# S32K324_M7 register map
Vendor: NXP Semiconductors; File version: 1.1
CPU: CM7 r0p1, little endian, MPU, FPU, VTOR, 4 interrupt priority bits
Registers are 32-bit, read-write, reset 0x0 unless marked. A register's access mark holds for its fields unless they carry their own. Offsets are from the block's base; [hi:lo] are bit positions; {n}, {i} and the like mark numbered series; 'fields as' and 'values as' point back to an identical list.

## SIUL2
Base 0x40290000
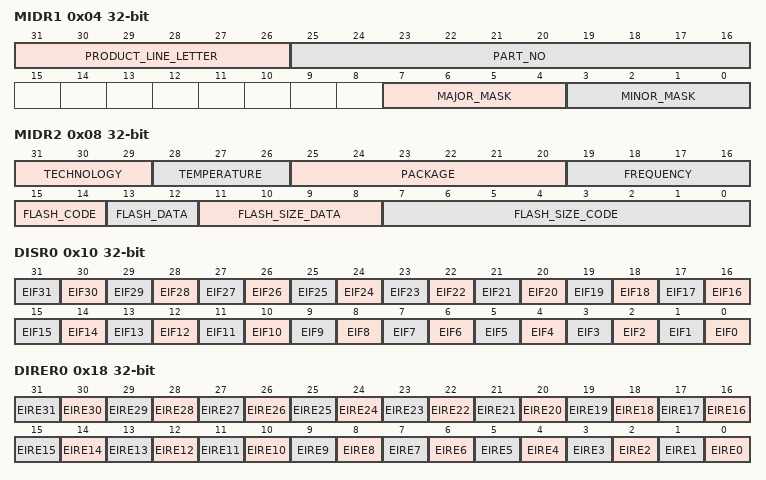
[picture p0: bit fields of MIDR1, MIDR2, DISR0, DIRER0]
0x04 MIDR1 ro reset not defined — SIUL2 MCU ID Register 1
  [31:26] PRODUCT_LINE_LETTER
  [25:16] PART_NO — MCU Part Number
  [7:4] MAJOR_MASK — Major Mask Revision
  [3:0] MINOR_MASK — Minor Mask Revision
0x08 MIDR2 ro reset not defined — SIUL2 MCU ID Register 2
  [31:29] TECHNOLOGY
    1=C40EFS3
  [28:26] TEMPERATURE
    4=M = 125C
  [25:20] PACKAGE
    3=257-MAPBGA; 35=100-MAXQFP; 38=172-MAXQFP
  [19:16] FREQUENCY
    3=120 MHz; 4=160 MHz; 5=240 MHz
  [15:14] FLASH_CODE
    2=Monolithic
  [13:12] FLASH_DATA
    2=Monolithic
  [11:8] FLASH_SIZE_DATA
    0=64KB; 1=128KB; 2=256KB
  [7:0] FLASH_SIZE_CODE
    2=512kB; 4=1MB; 8=2.00MB; 12=3.00MB; 16=4.00MB; 24=6.00MB; 32=8.00MB
0x10 DISR0 write-1-clears — SIUL2 DMA/Interrupt Status Flag Register0
  [n] EIF{n} write-1-clears (n=0..31) — External Interrupt Status Flag {n}
    0=EIF_NO (No interrupt event has occurred on the pad.); 1=EIF_YES (An interrupt event as defined by IREER{n} and IFEER{n} has occurred.)
0x18 DIRER0 — SIUL2 DMA/Interrupt Request Enable Register0
  [all] fields
    0=EIRE_DISABLED (Disabled); 1=EIRE_ENABLED (Enabled)
  [n] EIRE{n} (n=0..31) — External Interrupt Request Enable
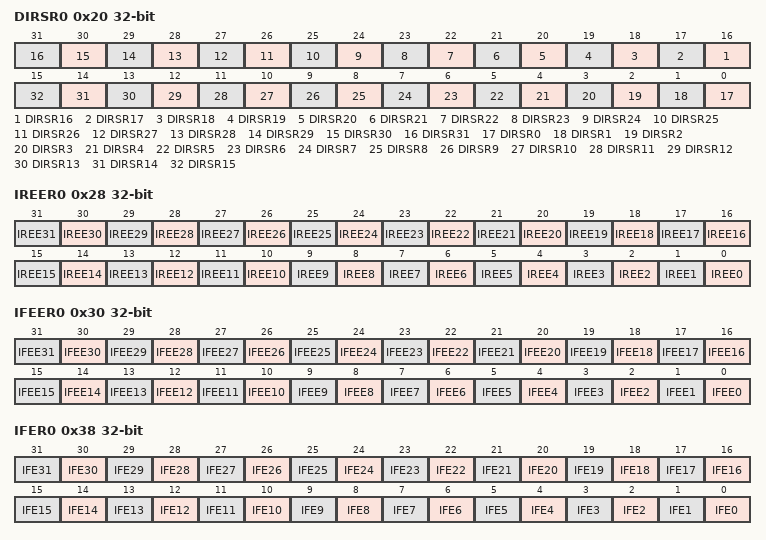
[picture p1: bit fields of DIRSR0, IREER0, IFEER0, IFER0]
0x20 DIRSR0 — SIUL2 DMA/Interrupt Request Select Register0
  [n] DIRSR{n} (n=16..31) — DMA/Interrupt Request Select Register
    0=DISR_INT (Interrupt request)
  [n] DIRSR{n} (n=0..15) — DMA/Interrupt Request Select Register
    0=DISR_INT (Interrupt request); 1=DISR_DMA (DMA request)
0x28 IREER0 — SIUL2 Interrupt Rising-Edge Event Enable Register 0
  [all] fields
    0=IREE_DISABLED (Disabled); 1=IREE_ENABLED (Enabled)
  [n] IREE{n} (n=0..31) — Enables rising-edge events to set DISR0[EIF{n}].
0x30 IFEER0 — SIUL2 Interrupt Falling-Edge Event Enable Register 0
  [all] fields
    0=IFEE_DISABLED (Disabled); 1=IFEE_ENABLED (Enabled)
  [n] IFEE{n} (n=0..31) — Enables falling-edge events to set DISR0[EIF{n}].
0x38 IFER0 — SIUL2 Interrupt Filter Enable Register 0
  [all] fields
    0=IFE_DISABLED (Disabled); 1=IFE_ENABLED (Enabled)
  [n] IFE{n} (n=0..31) — Enables digital glitch filter on the interrupt pad input.
{0x40+4i} IFMCR{i} (i=0..31) — SIUL2 Interrupt Filter Maximum Counter Register
  [3:0] MAXCNT — Maximum Interrupt Filter Counter setting
0xC0 IFCPR — SIUL2 Interrupt Filter Clock Prescaler Register
  [3:0] IFCP — Interrupt Filter Clock Prescaler setting
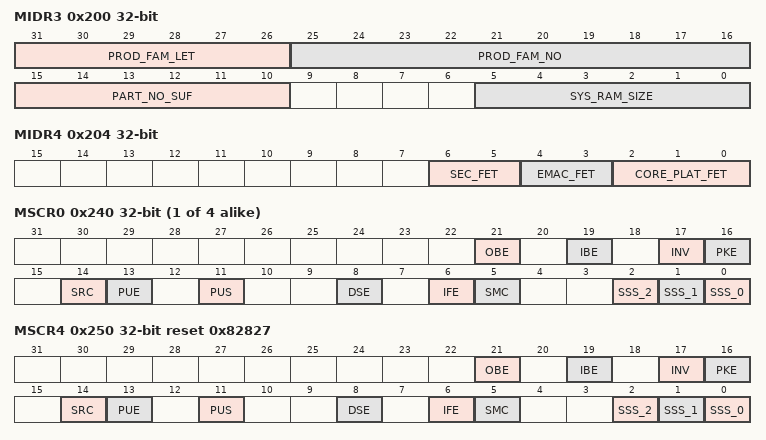
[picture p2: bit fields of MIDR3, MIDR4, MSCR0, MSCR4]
0x200 MIDR3 ro reset not defined — SIUL2 MCU ID Register 3
  [31:26] PROD_FAM_LET — Product Family Letter
    19=S
  [25:16] PROD_FAM_NO — Product Family Number
    32=32
  [15:10] PART_NO_SUF — Part Number Suffix
    0=None
  [5:0] SYS_RAM_SIZE — System RAM Size
    2=128kB; 3=192kB; 4=256kB; 6=512kB
0x204 MIDR4 ro reset not defined — SIUL2 MCU ID Register 4
  [6:5] SEC_FET — Security Feature
    1=HSE-B
  [4:3] EMAC_FET — Ethernet Feature
    0=No Ethernet; 1=Ethernet present
  [2:0] CORE_PLAT_FET — Core Platform Options Feature
    0=Single core; 1=Dual core; 2=1x lock-step core; 3=1x lock-step core + 1 perf. core; 4=Triple core
{0x240+4i} MSCR{i} (i=0..3) — SIUL2 Multiplexed Signal Configuration Register
  [21] OBE — GPIO Output Buffer Enable
    0=Output driver disabled; 1=Output driver enabled
  [19] IBE — Input Buffer Enable
    0=Disabled; 1=Enabled
  [17] INV — Invert
    0=Don't invert; 1=Invert
  [16] PKE — Pad keeping enable
    0=Disabled; 1=Enabled
  [14] SRC — Slew Rate Control
    0=Fastest setting; 1=Slowest setting
  [13] PUE — Pull Enable
    0=Disabled; 1=Enabled
  [11] PUS — Pull Select
    0=Pull down; 1=Pull up
  [8] DSE
    0=Disabled; 1=Enabled
  [6] IFE
    0=Disabled; 1=Enabled
  [5] SMC — Safe Mode Control
    0=Disable (The output buffer returns to its previous state when the chip leaves Safe mode.); 1=Don't disable
  [2] SSS_2 — Source Signal Select_2
  [1] SSS_1 — Source Signal Select_1
  [0] SSS_0 — Source Signal Select_0
0x250 MSCR4 reset 0x82827 — SIUL2 Multiplexed Signal Configuration Register
  fields as MSCR0
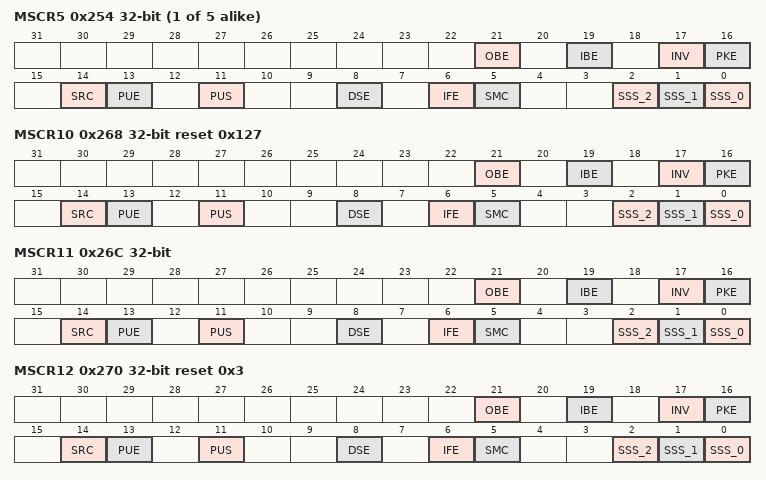
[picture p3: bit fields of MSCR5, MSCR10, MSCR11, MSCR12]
{0x240+4i} MSCR{i} (i=5..9) — SIUL2 Multiplexed Signal Configuration Register
  fields as MSCR0
0x268 MSCR10 reset 0x127 — SIUL2 Multiplexed Signal Configuration Register
  fields as MSCR0
0x26C MSCR11 — SIUL2 Multiplexed Signal Configuration Register
  fields as MSCR0
0x270 MSCR12 reset 0x3 — SIUL2 Multiplexed Signal Configuration Register
  fields as MSCR0
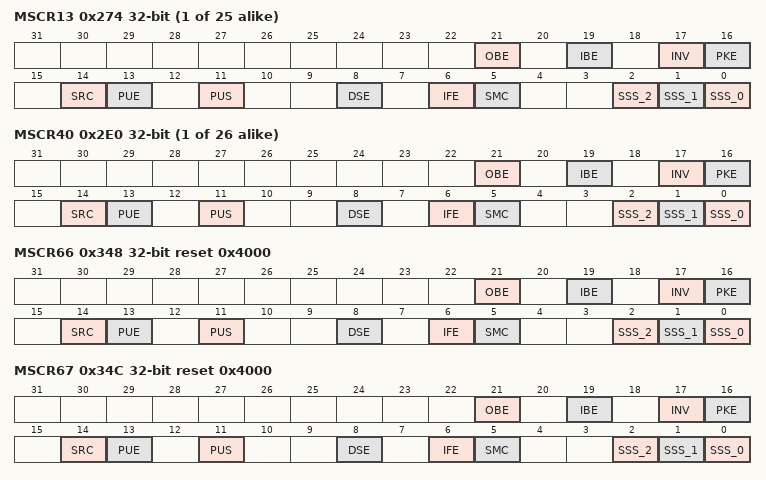
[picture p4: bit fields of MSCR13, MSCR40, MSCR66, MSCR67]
{0x240+4i} MSCR{i} (i=13..37) — SIUL2 Multiplexed Signal Configuration Register
  fields as MSCR0
{0x240+4i} MSCR{i} (i=40..65) — SIUL2 Multiplexed Signal Configuration Register
  fields as MSCR0
0x348 MSCR66 reset 0x4000 — SIUL2 Multiplexed Signal Configuration Register
  fields as MSCR0
0x34C MSCR67 reset 0x4000 — SIUL2 Multiplexed Signal Configuration Register
  fields as MSCR0
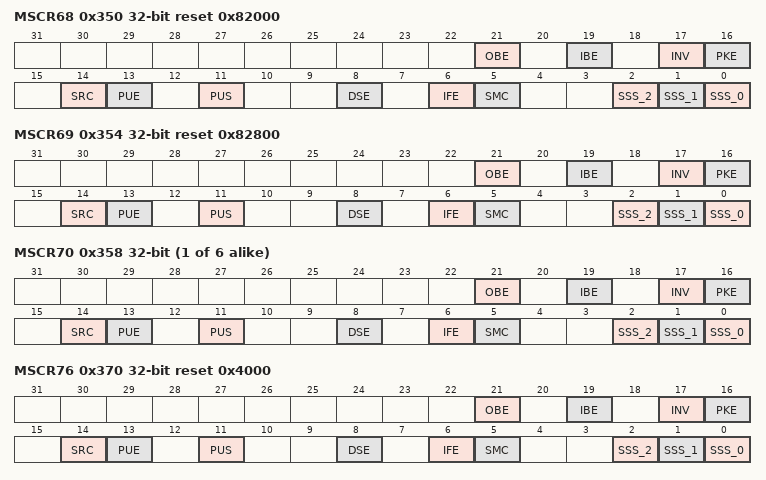
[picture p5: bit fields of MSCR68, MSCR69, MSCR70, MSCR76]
0x350 MSCR68 reset 0x82000 — SIUL2 Multiplexed Signal Configuration Register
  fields as MSCR0
0x354 MSCR69 reset 0x82800 — SIUL2 Multiplexed Signal Configuration Register
  fields as MSCR0
{0x240+4i} MSCR{i} (i=70..75) — SIUL2 Multiplexed Signal Configuration Register
  fields as MSCR0
0x370 MSCR76 reset 0x4000 — SIUL2 Multiplexed Signal Configuration Register
  fields as MSCR0
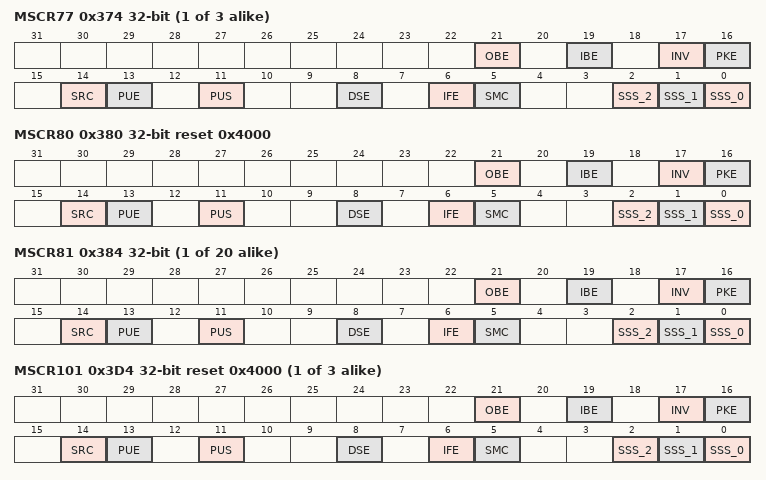
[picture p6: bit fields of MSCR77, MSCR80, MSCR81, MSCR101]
{0x240+4i} MSCR{i} (i=77..79) — SIUL2 Multiplexed Signal Configuration Register
  fields as MSCR0
0x380 MSCR80 reset 0x4000 — SIUL2 Multiplexed Signal Configuration Register
  fields as MSCR0
{0x240+4i} MSCR{i} (i=81..100) — SIUL2 Multiplexed Signal Configuration Register
  fields as MSCR0
{0x240+4i} MSCR{i} reset 0x4000 (i=101..103) — SIUL2 Multiplexed Signal Configuration Register
  fields as MSCR0
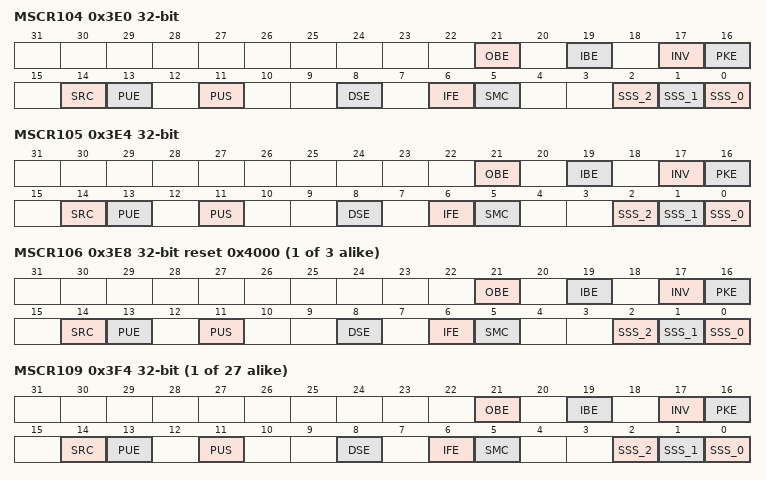
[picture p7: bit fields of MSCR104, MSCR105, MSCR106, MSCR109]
0x3E0 MSCR104 — SIUL2 Multiplexed Signal Configuration Register
  fields as MSCR0
0x3E4 MSCR105 — SIUL2 Multiplexed Signal Configuration Register
  fields as MSCR0
{0x240+4i} MSCR{i} reset 0x4000 (i=106..108) — SIUL2 Multiplexed Signal Configuration Register
  fields as MSCR0
{0x240+4i} MSCR{i} (i=109..135) — SIUL2 Multiplexed Signal Configuration Register
  fields as MSCR0
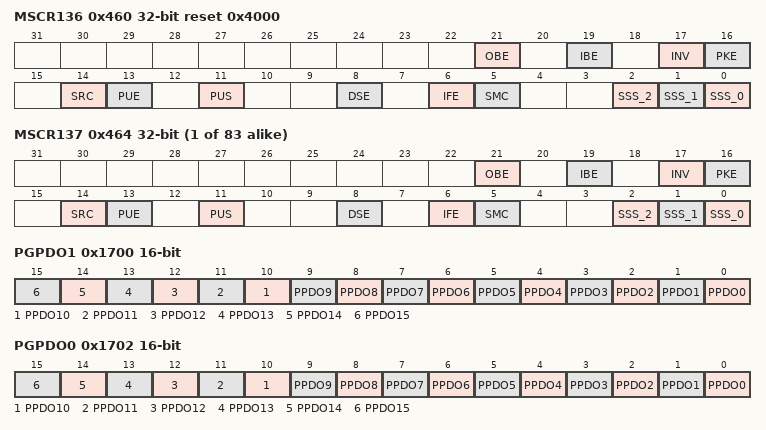
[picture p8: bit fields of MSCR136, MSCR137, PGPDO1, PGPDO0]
0x460 MSCR136 reset 0x4000 — SIUL2 Multiplexed Signal Configuration Register
  fields as MSCR0
{0x240+4i} MSCR{i} (i=137..219) — SIUL2 Multiplexed Signal Configuration Register
  fields as MSCR0
{0xA40+4i} IMCR{i} (i=0..5) — SIUL2 Input Multiplexed Signal Configuration Register
  [3:0] SSS — Source Signal Select
{0xA40+4i} IMCR{i} (i=16..71) — SIUL2 Input Multiplexed Signal Configuration Register
  [3:0] SSS — Source Signal Select
{0xA40+4i} IMCR{i} (i=80..103) — SIUL2 Input Multiplexed Signal Configuration Register
  [3:0] SSS — Source Signal Select
{0xA40+4i} IMCR{i} (i=112..135) — SIUL2 Input Multiplexed Signal Configuration Register
  [3:0] SSS — Source Signal Select
{0xA40+4i} IMCR{i} (i=144..149) — SIUL2 Input Multiplexed Signal Configuration Register
  [3:0] SSS — Source Signal Select
{0xA40+4i} IMCR{i} (i=152..202) — SIUL2 Input Multiplexed Signal Configuration Register
  [3:0] SSS — Source Signal Select
{0xA40+4i} IMCR{i} (i=211..268) — SIUL2 Input Multiplexed Signal Configuration Register
  [3:0] SSS — Source Signal Select
{0xA40+4i} IMCR{i} (i=289..309) — SIUL2 Input Multiplexed Signal Configuration Register
  [3:0] SSS — Source Signal Select
{0xA40+4i} IMCR{i} (i=315..325) — SIUL2 Input Multiplexed Signal Configuration Register
  [3:0] SSS — Source Signal Select
{0xA40+4i} IMCR{i} (i=343..378) — SIUL2 Input Multiplexed Signal Configuration Register
  [3:0] SSS — Source Signal Select
0x1300 GPDO3 8-bit — SIUL2 GPIO Pad Data Output Register
  [0] PDO_n — Pad Data Out
    0=PDO_a_LOW (Pad Data Out Low); 1=PDO_a_HIGH (Pad Data Out High)
0x1301 GPDO2 8-bit — SIUL2 GPIO Pad Data Output Register
  fields as GPDO3
0x1302 GPDO1 8-bit — SIUL2 GPIO Pad Data Output Register
  fields as GPDO3
0x1303 GPDO0 8-bit — SIUL2 GPIO Pad Data Output Register
  fields as GPDO3
0x1304 GPDO7 8-bit — SIUL2 GPIO Pad Data Output Register
  fields as GPDO3
0x1305 GPDO6 8-bit — SIUL2 GPIO Pad Data Output Register
  fields as GPDO3
0x1306 GPDO5 8-bit — SIUL2 GPIO Pad Data Output Register
  fields as GPDO3
0x1307 GPDO4 8-bit — SIUL2 GPIO Pad Data Output Register
  fields as GPDO3
0x1308 GPDO11 8-bit — SIUL2 GPIO Pad Data Output Register
  fields as GPDO3
0x1309 GPDO10 8-bit — SIUL2 GPIO Pad Data Output Register
  fields as GPDO3
0x130A GPDO9 8-bit — SIUL2 GPIO Pad Data Output Register
  fields as GPDO3
0x130B GPDO8 8-bit — SIUL2 GPIO Pad Data Output Register
  fields as GPDO3
0x130C GPDO15 8-bit — SIUL2 GPIO Pad Data Output Register
  fields as GPDO3
0x130D GPDO14 8-bit — SIUL2 GPIO Pad Data Output Register
  fields as GPDO3
0x130E GPDO13 8-bit — SIUL2 GPIO Pad Data Output Register
  fields as GPDO3
0x130F GPDO12 8-bit — SIUL2 GPIO Pad Data Output Register
  fields as GPDO3
0x1310 GPDO19 8-bit — SIUL2 GPIO Pad Data Output Register
  fields as GPDO3
0x1311 GPDO18 8-bit — SIUL2 GPIO Pad Data Output Register
  fields as GPDO3
0x1312 GPDO17 8-bit — SIUL2 GPIO Pad Data Output Register
  fields as GPDO3
0x1313 GPDO16 8-bit — SIUL2 GPIO Pad Data Output Register
  fields as GPDO3
0x1314 GPDO23 8-bit — SIUL2 GPIO Pad Data Output Register
  fields as GPDO3
0x1315 GPDO22 8-bit — SIUL2 GPIO Pad Data Output Register
  fields as GPDO3
0x1316 GPDO21 8-bit — SIUL2 GPIO Pad Data Output Register
  fields as GPDO3
0x1317 GPDO20 8-bit — SIUL2 GPIO Pad Data Output Register
  fields as GPDO3
0x1318 GPDO27 8-bit — SIUL2 GPIO Pad Data Output Register
  fields as GPDO3
0x1319 GPDO26 8-bit — SIUL2 GPIO Pad Data Output Register
  fields as GPDO3
0x131A GPDO25 8-bit — SIUL2 GPIO Pad Data Output Register
  fields as GPDO3
0x131B GPDO24 8-bit — SIUL2 GPIO Pad Data Output Register
  fields as GPDO3
0x131C GPDO31 8-bit — SIUL2 GPIO Pad Data Output Register
  fields as GPDO3
0x131D GPDO30 8-bit — SIUL2 GPIO Pad Data Output Register
  fields as GPDO3
0x131E GPDO29 8-bit — SIUL2 GPIO Pad Data Output Register
  fields as GPDO3
0x131F GPDO28 8-bit — SIUL2 GPIO Pad Data Output Register
  fields as GPDO3
0x1320 GPDO35 8-bit — SIUL2 GPIO Pad Data Output Register
  fields as GPDO3
0x1321 GPDO34 8-bit — SIUL2 GPIO Pad Data Output Register
  fields as GPDO3
0x1322 GPDO33 8-bit — SIUL2 GPIO Pad Data Output Register
  fields as GPDO3
0x1323 GPDO32 8-bit — SIUL2 GPIO Pad Data Output Register
  fields as GPDO3
0x1326 GPDO37 8-bit — SIUL2 GPIO Pad Data Output Register
  fields as GPDO3
0x1327 GPDO36 8-bit — SIUL2 GPIO Pad Data Output Register
  fields as GPDO3
0x1328 GPDO43 8-bit — SIUL2 GPIO Pad Data Output Register
  fields as GPDO3
0x1329 GPDO42 8-bit — SIUL2 GPIO Pad Data Output Register
  fields as GPDO3
0x132A GPDO41 8-bit — SIUL2 GPIO Pad Data Output Register
  fields as GPDO3
0x132B GPDO40 8-bit — SIUL2 GPIO Pad Data Output Register
  fields as GPDO3
0x132C GPDO47 8-bit — SIUL2 GPIO Pad Data Output Register
  fields as GPDO3
0x132D GPDO46 8-bit — SIUL2 GPIO Pad Data Output Register
  fields as GPDO3
0x132E GPDO45 8-bit — SIUL2 GPIO Pad Data Output Register
  fields as GPDO3
0x132F GPDO44 8-bit — SIUL2 GPIO Pad Data Output Register
  fields as GPDO3
0x1330 GPDO51 8-bit — SIUL2 GPIO Pad Data Output Register
  fields as GPDO3
0x1331 GPDO50 8-bit — SIUL2 GPIO Pad Data Output Register
  fields as GPDO3
0x1332 GPDO49 8-bit — SIUL2 GPIO Pad Data Output Register
  fields as GPDO3
0x1333 GPDO48 8-bit — SIUL2 GPIO Pad Data Output Register
  fields as GPDO3
0x1334 GPDO55 8-bit — SIUL2 GPIO Pad Data Output Register
  fields as GPDO3
0x1335 GPDO54 8-bit — SIUL2 GPIO Pad Data Output Register
  fields as GPDO3
0x1336 GPDO53 8-bit — SIUL2 GPIO Pad Data Output Register
  fields as GPDO3
0x1337 GPDO52 8-bit — SIUL2 GPIO Pad Data Output Register
  fields as GPDO3
0x1338 GPDO59 8-bit — SIUL2 GPIO Pad Data Output Register
  fields as GPDO3
0x1339 GPDO58 8-bit — SIUL2 GPIO Pad Data Output Register
  fields as GPDO3
0x133A GPDO57 8-bit — SIUL2 GPIO Pad Data Output Register
  fields as GPDO3
0x133B GPDO56 8-bit — SIUL2 GPIO Pad Data Output Register
  fields as GPDO3
0x133C GPDO63 8-bit — SIUL2 GPIO Pad Data Output Register
  fields as GPDO3
0x133D GPDO62 8-bit — SIUL2 GPIO Pad Data Output Register
  fields as GPDO3
0x133E GPDO61 8-bit — SIUL2 GPIO Pad Data Output Register
  fields as GPDO3
0x133F GPDO60 8-bit — SIUL2 GPIO Pad Data Output Register
  fields as GPDO3
0x1340 GPDO67 8-bit — SIUL2 GPIO Pad Data Output Register
  fields as GPDO3
0x1341 GPDO66 8-bit — SIUL2 GPIO Pad Data Output Register
  fields as GPDO3
0x1342 GPDO65 8-bit — SIUL2 GPIO Pad Data Output Register
  fields as GPDO3
0x1343 GPDO64 8-bit — SIUL2 GPIO Pad Data Output Register
  fields as GPDO3
0x1344 GPDO71 8-bit — SIUL2 GPIO Pad Data Output Register
  fields as GPDO3
0x1345 GPDO70 8-bit — SIUL2 GPIO Pad Data Output Register
  fields as GPDO3
0x1346 GPDO69 8-bit — SIUL2 GPIO Pad Data Output Register
  fields as GPDO3
0x1347 GPDO68 8-bit — SIUL2 GPIO Pad Data Output Register
  fields as GPDO3
0x1348 GPDO75 8-bit — SIUL2 GPIO Pad Data Output Register
  fields as GPDO3
0x1349 GPDO74 8-bit — SIUL2 GPIO Pad Data Output Register
  fields as GPDO3
0x134A GPDO73 8-bit — SIUL2 GPIO Pad Data Output Register
  fields as GPDO3
0x134B GPDO72 8-bit — SIUL2 GPIO Pad Data Output Register
  fields as GPDO3
0x134C GPDO79 8-bit — SIUL2 GPIO Pad Data Output Register
  fields as GPDO3
0x134D GPDO78 8-bit — SIUL2 GPIO Pad Data Output Register
  fields as GPDO3
0x134E GPDO77 8-bit — SIUL2 GPIO Pad Data Output Register
  fields as GPDO3
0x134F GPDO76 8-bit — SIUL2 GPIO Pad Data Output Register
  fields as GPDO3
0x1350 GPDO83 8-bit — SIUL2 GPIO Pad Data Output Register
  fields as GPDO3
0x1351 GPDO82 8-bit — SIUL2 GPIO Pad Data Output Register
  fields as GPDO3
0x1352 GPDO81 8-bit — SIUL2 GPIO Pad Data Output Register
  fields as GPDO3
0x1353 GPDO80 8-bit — SIUL2 GPIO Pad Data Output Register
  fields as GPDO3
0x1354 GPDO87 8-bit — SIUL2 GPIO Pad Data Output Register
  fields as GPDO3
0x1355 GPDO86 8-bit — SIUL2 GPIO Pad Data Output Register
  fields as GPDO3
0x1356 GPDO85 8-bit — SIUL2 GPIO Pad Data Output Register
  fields as GPDO3
0x1357 GPDO84 8-bit — SIUL2 GPIO Pad Data Output Register
  fields as GPDO3
0x1358 GPDO91 8-bit — SIUL2 GPIO Pad Data Output Register
  fields as GPDO3
0x1359 GPDO90 8-bit — SIUL2 GPIO Pad Data Output Register
  fields as GPDO3
0x135A GPDO89 8-bit — SIUL2 GPIO Pad Data Output Register
  fields as GPDO3
0x135B GPDO88 8-bit — SIUL2 GPIO Pad Data Output Register
  fields as GPDO3
0x135C GPDO95 8-bit — SIUL2 GPIO Pad Data Output Register
  fields as GPDO3
0x135D GPDO94 8-bit — SIUL2 GPIO Pad Data Output Register
  fields as GPDO3
0x135E GPDO93 8-bit — SIUL2 GPIO Pad Data Output Register
  fields as GPDO3
0x135F GPDO92 8-bit — SIUL2 GPIO Pad Data Output Register
  fields as GPDO3
0x1360 GPDO99 8-bit — SIUL2 GPIO Pad Data Output Register
  fields as GPDO3
0x1361 GPDO98 8-bit — SIUL2 GPIO Pad Data Output Register
  fields as GPDO3
0x1362 GPDO97 8-bit — SIUL2 GPIO Pad Data Output Register
  fields as GPDO3
0x1363 GPDO96 8-bit — SIUL2 GPIO Pad Data Output Register
  fields as GPDO3
0x1364 GPDO103 8-bit — SIUL2 GPIO Pad Data Output Register
  fields as GPDO3
0x1365 GPDO102 8-bit — SIUL2 GPIO Pad Data Output Register
  fields as GPDO3
0x1366 GPDO101 8-bit — SIUL2 GPIO Pad Data Output Register
  fields as GPDO3
0x1367 GPDO100 8-bit — SIUL2 GPIO Pad Data Output Register
  fields as GPDO3
0x1368 GPDO107 8-bit — SIUL2 GPIO Pad Data Output Register
  fields as GPDO3
0x1369 GPDO106 8-bit — SIUL2 GPIO Pad Data Output Register
  fields as GPDO3
0x136A GPDO105 8-bit — SIUL2 GPIO Pad Data Output Register
  fields as GPDO3
0x136B GPDO104 8-bit — SIUL2 GPIO Pad Data Output Register
  fields as GPDO3
0x136C GPDO111 8-bit — SIUL2 GPIO Pad Data Output Register
  fields as GPDO3
0x136D GPDO110 8-bit — SIUL2 GPIO Pad Data Output Register
  fields as GPDO3
0x136E GPDO109 8-bit — SIUL2 GPIO Pad Data Output Register
  fields as GPDO3
0x136F GPDO108 8-bit — SIUL2 GPIO Pad Data Output Register
  fields as GPDO3
0x1370 GPDO115 8-bit — SIUL2 GPIO Pad Data Output Register
  fields as GPDO3
0x1371 GPDO114 8-bit — SIUL2 GPIO Pad Data Output Register
  fields as GPDO3
0x1372 GPDO113 8-bit — SIUL2 GPIO Pad Data Output Register
  fields as GPDO3
0x1373 GPDO112 8-bit — SIUL2 GPIO Pad Data Output Register
  fields as GPDO3
0x1374 GPDO119 8-bit — SIUL2 GPIO Pad Data Output Register
  fields as GPDO3
0x1375 GPDO118 8-bit — SIUL2 GPIO Pad Data Output Register
  fields as GPDO3
0x1376 GPDO117 8-bit — SIUL2 GPIO Pad Data Output Register
  fields as GPDO3
0x1377 GPDO116 8-bit — SIUL2 GPIO Pad Data Output Register
  fields as GPDO3
0x1378 GPDO123 8-bit — SIUL2 GPIO Pad Data Output Register
  fields as GPDO3
0x1379 GPDO122 8-bit — SIUL2 GPIO Pad Data Output Register
  fields as GPDO3
0x137A GPDO121 8-bit — SIUL2 GPIO Pad Data Output Register
  fields as GPDO3
0x137B GPDO120 8-bit — SIUL2 GPIO Pad Data Output Register
  fields as GPDO3
0x137C GPDO127 8-bit — SIUL2 GPIO Pad Data Output Register
  fields as GPDO3
0x137D GPDO126 8-bit — SIUL2 GPIO Pad Data Output Register
  fields as GPDO3
0x137E GPDO125 8-bit — SIUL2 GPIO Pad Data Output Register
  fields as GPDO3
0x137F GPDO124 8-bit — SIUL2 GPIO Pad Data Output Register
  fields as GPDO3
0x1380 GPDO131 8-bit — SIUL2 GPIO Pad Data Output Register
  fields as GPDO3
0x1381 GPDO130 8-bit — SIUL2 GPIO Pad Data Output Register
  fields as GPDO3
0x1382 GPDO129 8-bit — SIUL2 GPIO Pad Data Output Register
  fields as GPDO3
0x1383 GPDO128 8-bit — SIUL2 GPIO Pad Data Output Register
  fields as GPDO3
0x1384 GPDO135 8-bit — SIUL2 GPIO Pad Data Output Register
  fields as GPDO3
0x1385 GPDO134 8-bit — SIUL2 GPIO Pad Data Output Register
  fields as GPDO3
0x1386 GPDO133 8-bit — SIUL2 GPIO Pad Data Output Register
  fields as GPDO3
0x1387 GPDO132 8-bit — SIUL2 GPIO Pad Data Output Register
  fields as GPDO3
0x1388 GPDO139 8-bit — SIUL2 GPIO Pad Data Output Register
  fields as GPDO3
0x1389 GPDO138 8-bit — SIUL2 GPIO Pad Data Output Register
  fields as GPDO3
0x138A GPDO137 8-bit — SIUL2 GPIO Pad Data Output Register
  fields as GPDO3
0x138B GPDO136 8-bit — SIUL2 GPIO Pad Data Output Register
  fields as GPDO3
0x138C GPDO143 8-bit — SIUL2 GPIO Pad Data Output Register
  fields as GPDO3
0x138D GPDO142 8-bit — SIUL2 GPIO Pad Data Output Register
  fields as GPDO3
0x138E GPDO141 8-bit — SIUL2 GPIO Pad Data Output Register
  fields as GPDO3
0x138F GPDO140 8-bit — SIUL2 GPIO Pad Data Output Register
  fields as GPDO3
0x1390 GPDO147 8-bit — SIUL2 GPIO Pad Data Output Register
  fields as GPDO3
0x1391 GPDO146 8-bit — SIUL2 GPIO Pad Data Output Register
  fields as GPDO3
0x1392 GPDO145 8-bit — SIUL2 GPIO Pad Data Output Register
  fields as GPDO3
0x1393 GPDO144 8-bit — SIUL2 GPIO Pad Data Output Register
  fields as GPDO3
0x1394 GPDO151 8-bit — SIUL2 GPIO Pad Data Output Register
  fields as GPDO3
0x1395 GPDO150 8-bit — SIUL2 GPIO Pad Data Output Register
  fields as GPDO3
0x1396 GPDO149 8-bit — SIUL2 GPIO Pad Data Output Register
  fields as GPDO3
0x1397 GPDO148 8-bit — SIUL2 GPIO Pad Data Output Register
  fields as GPDO3
0x1398 GPDO155 8-bit — SIUL2 GPIO Pad Data Output Register
  fields as GPDO3
0x1399 GPDO154 8-bit — SIUL2 GPIO Pad Data Output Register
  fields as GPDO3
0x139A GPDO153 8-bit — SIUL2 GPIO Pad Data Output Register
  fields as GPDO3
0x139B GPDO152 8-bit — SIUL2 GPIO Pad Data Output Register
  fields as GPDO3
0x139C GPDO159 8-bit — SIUL2 GPIO Pad Data Output Register
  fields as GPDO3
0x139D GPDO158 8-bit — SIUL2 GPIO Pad Data Output Register
  fields as GPDO3
0x139E GPDO157 8-bit — SIUL2 GPIO Pad Data Output Register
  fields as GPDO3
0x139F GPDO156 8-bit — SIUL2 GPIO Pad Data Output Register
  fields as GPDO3
0x13A0 GPDO163 8-bit — SIUL2 GPIO Pad Data Output Register
  fields as GPDO3
0x13A1 GPDO162 8-bit — SIUL2 GPIO Pad Data Output Register
  fields as GPDO3
0x13A2 GPDO161 8-bit — SIUL2 GPIO Pad Data Output Register
  fields as GPDO3
0x13A3 GPDO160 8-bit — SIUL2 GPIO Pad Data Output Register
  fields as GPDO3
0x13A4 GPDO167 8-bit — SIUL2 GPIO Pad Data Output Register
  fields as GPDO3
0x13A5 GPDO166 8-bit — SIUL2 GPIO Pad Data Output Register
  fields as GPDO3
0x13A6 GPDO165 8-bit — SIUL2 GPIO Pad Data Output Register
  fields as GPDO3
0x13A7 GPDO164 8-bit — SIUL2 GPIO Pad Data Output Register
  fields as GPDO3
0x13A8 GPDO171 8-bit — SIUL2 GPIO Pad Data Output Register
  fields as GPDO3
0x13A9 GPDO170 8-bit — SIUL2 GPIO Pad Data Output Register
  fields as GPDO3
0x13AA GPDO169 8-bit — SIUL2 GPIO Pad Data Output Register
  fields as GPDO3
0x13AB GPDO168 8-bit — SIUL2 GPIO Pad Data Output Register
  fields as GPDO3
0x13AC GPDO175 8-bit — SIUL2 GPIO Pad Data Output Register
  fields as GPDO3
0x13AD GPDO174 8-bit — SIUL2 GPIO Pad Data Output Register
  fields as GPDO3
0x13AE GPDO173 8-bit — SIUL2 GPIO Pad Data Output Register
  fields as GPDO3
0x13AF GPDO172 8-bit — SIUL2 GPIO Pad Data Output Register
  fields as GPDO3
0x13B0 GPDO179 8-bit — SIUL2 GPIO Pad Data Output Register
  fields as GPDO3
0x13B1 GPDO178 8-bit — SIUL2 GPIO Pad Data Output Register
  fields as GPDO3
0x13B2 GPDO177 8-bit — SIUL2 GPIO Pad Data Output Register
  fields as GPDO3
0x13B3 GPDO176 8-bit — SIUL2 GPIO Pad Data Output Register
  fields as GPDO3
0x13B4 GPDO183 8-bit — SIUL2 GPIO Pad Data Output Register
  fields as GPDO3
0x13B5 GPDO182 8-bit — SIUL2 GPIO Pad Data Output Register
  fields as GPDO3
0x13B6 GPDO181 8-bit — SIUL2 GPIO Pad Data Output Register
  fields as GPDO3
0x13B7 GPDO180 8-bit — SIUL2 GPIO Pad Data Output Register
  fields as GPDO3
0x13B8 GPDO187 8-bit — SIUL2 GPIO Pad Data Output Register
  fields as GPDO3
0x13B9 GPDO186 8-bit — SIUL2 GPIO Pad Data Output Register
  fields as GPDO3
0x13BA GPDO185 8-bit — SIUL2 GPIO Pad Data Output Register
  fields as GPDO3
0x13BB GPDO184 8-bit — SIUL2 GPIO Pad Data Output Register
  fields as GPDO3
0x13BC GPDO191 8-bit — SIUL2 GPIO Pad Data Output Register
  fields as GPDO3
0x13BD GPDO190 8-bit — SIUL2 GPIO Pad Data Output Register
  fields as GPDO3
0x13BE GPDO189 8-bit — SIUL2 GPIO Pad Data Output Register
  fields as GPDO3
0x13BF GPDO188 8-bit — SIUL2 GPIO Pad Data Output Register
  fields as GPDO3
0x13C0 GPDO195 8-bit — SIUL2 GPIO Pad Data Output Register
  fields as GPDO3
0x13C1 GPDO194 8-bit — SIUL2 GPIO Pad Data Output Register
  fields as GPDO3
0x13C2 GPDO193 8-bit — SIUL2 GPIO Pad Data Output Register
  fields as GPDO3
0x13C3 GPDO192 8-bit — SIUL2 GPIO Pad Data Output Register
  fields as GPDO3
0x13C4 GPDO199 8-bit — SIUL2 GPIO Pad Data Output Register
  fields as GPDO3
0x13C5 GPDO198 8-bit — SIUL2 GPIO Pad Data Output Register
  fields as GPDO3
0x13C6 GPDO197 8-bit — SIUL2 GPIO Pad Data Output Register
  fields as GPDO3
0x13C7 GPDO196 8-bit — SIUL2 GPIO Pad Data Output Register
  fields as GPDO3
0x13C8 GPDO203 8-bit — SIUL2 GPIO Pad Data Output Register
  fields as GPDO3
0x13C9 GPDO202 8-bit — SIUL2 GPIO Pad Data Output Register
  fields as GPDO3
0x13CA GPDO201 8-bit — SIUL2 GPIO Pad Data Output Register
  fields as GPDO3
0x13CB GPDO200 8-bit — SIUL2 GPIO Pad Data Output Register
  fields as GPDO3
0x13CC GPDO207 8-bit — SIUL2 GPIO Pad Data Output Register
  fields as GPDO3
0x13CD GPDO206 8-bit — SIUL2 GPIO Pad Data Output Register
  fields as GPDO3
0x13CE GPDO205 8-bit — SIUL2 GPIO Pad Data Output Register
  fields as GPDO3
0x13CF GPDO204 8-bit — SIUL2 GPIO Pad Data Output Register
  fields as GPDO3
0x13D0 GPDO211 8-bit — SIUL2 GPIO Pad Data Output Register
  fields as GPDO3
0x13D1 GPDO210 8-bit — SIUL2 GPIO Pad Data Output Register
  fields as GPDO3
0x13D2 GPDO209 8-bit — SIUL2 GPIO Pad Data Output Register
  fields as GPDO3
0x13D3 GPDO208 8-bit — SIUL2 GPIO Pad Data Output Register
  fields as GPDO3
0x13D4 GPDO215 8-bit — SIUL2 GPIO Pad Data Output Register
  fields as GPDO3
0x13D5 GPDO214 8-bit — SIUL2 GPIO Pad Data Output Register
  fields as GPDO3
0x13D6 GPDO213 8-bit — SIUL2 GPIO Pad Data Output Register
  fields as GPDO3
0x13D7 GPDO212 8-bit — SIUL2 GPIO Pad Data Output Register
  fields as GPDO3
0x13D8 GPDO219 8-bit — SIUL2 GPIO Pad Data Output Register
  fields as GPDO3
0x13D9 GPDO218 8-bit — SIUL2 GPIO Pad Data Output Register
  fields as GPDO3
0x13DA GPDO217 8-bit — SIUL2 GPIO Pad Data Output Register
  fields as GPDO3
0x13DB GPDO216 8-bit — SIUL2 GPIO Pad Data Output Register
  fields as GPDO3
0x1500 GPDI3 8-bit ro — SIUL2 GPIO Pad Data Input Register
  [0] PDI_n — Pad Data In
    0=PDI_a_LOW (Pad Data In Low); 1=PDI_a_HIGH (Pad Data In High)
0x1501 GPDI2 8-bit ro — SIUL2 GPIO Pad Data Input Register
  fields as GPDI3
0x1502 GPDI1 8-bit ro — SIUL2 GPIO Pad Data Input Register
  fields as GPDI3
0x1503 GPDI0 8-bit ro — SIUL2 GPIO Pad Data Input Register
  fields as GPDI3
0x1504 GPDI7 8-bit ro — SIUL2 GPIO Pad Data Input Register
  fields as GPDI3
0x1505 GPDI6 8-bit ro — SIUL2 GPIO Pad Data Input Register
  fields as GPDI3
0x1506 GPDI5 8-bit ro — SIUL2 GPIO Pad Data Input Register
  fields as GPDI3
0x1507 GPDI4 8-bit ro — SIUL2 GPIO Pad Data Input Register
  fields as GPDI3
0x1508 GPDI11 8-bit ro — SIUL2 GPIO Pad Data Input Register
  fields as GPDI3
0x1509 GPDI10 8-bit ro — SIUL2 GPIO Pad Data Input Register
  fields as GPDI3
0x150A GPDI9 8-bit ro — SIUL2 GPIO Pad Data Input Register
  fields as GPDI3
0x150B GPDI8 8-bit ro — SIUL2 GPIO Pad Data Input Register
  fields as GPDI3
0x150C GPDI15 8-bit ro — SIUL2 GPIO Pad Data Input Register
  fields as GPDI3
0x150D GPDI14 8-bit ro — SIUL2 GPIO Pad Data Input Register
  fields as GPDI3
0x150E GPDI13 8-bit ro — SIUL2 GPIO Pad Data Input Register
  fields as GPDI3
0x150F GPDI12 8-bit ro — SIUL2 GPIO Pad Data Input Register
  fields as GPDI3
0x1510 GPDI19 8-bit ro — SIUL2 GPIO Pad Data Input Register
  fields as GPDI3
0x1511 GPDI18 8-bit ro — SIUL2 GPIO Pad Data Input Register
  fields as GPDI3
0x1512 GPDI17 8-bit ro — SIUL2 GPIO Pad Data Input Register
  fields as GPDI3
0x1513 GPDI16 8-bit ro — SIUL2 GPIO Pad Data Input Register
  fields as GPDI3
0x1514 GPDI23 8-bit ro — SIUL2 GPIO Pad Data Input Register
  fields as GPDI3
0x1515 GPDI22 8-bit ro — SIUL2 GPIO Pad Data Input Register
  fields as GPDI3
0x1516 GPDI21 8-bit ro — SIUL2 GPIO Pad Data Input Register
  fields as GPDI3
0x1517 GPDI20 8-bit ro — SIUL2 GPIO Pad Data Input Register
  fields as GPDI3
0x1518 GPDI27 8-bit ro — SIUL2 GPIO Pad Data Input Register
  fields as GPDI3
0x1519 GPDI26 8-bit ro — SIUL2 GPIO Pad Data Input Register
  fields as GPDI3
0x151A GPDI25 8-bit ro — SIUL2 GPIO Pad Data Input Register
  fields as GPDI3
0x151B GPDI24 8-bit ro — SIUL2 GPIO Pad Data Input Register
  fields as GPDI3
0x151C GPDI31 8-bit ro — SIUL2 GPIO Pad Data Input Register
  fields as GPDI3
0x151D GPDI30 8-bit ro — SIUL2 GPIO Pad Data Input Register
  fields as GPDI3
0x151E GPDI29 8-bit ro — SIUL2 GPIO Pad Data Input Register
  fields as GPDI3
0x151F GPDI28 8-bit ro — SIUL2 GPIO Pad Data Input Register
  fields as GPDI3
0x1520 GPDI35 8-bit ro — SIUL2 GPIO Pad Data Input Register
  fields as GPDI3
0x1521 GPDI34 8-bit ro — SIUL2 GPIO Pad Data Input Register
  fields as GPDI3
0x1522 GPDI33 8-bit ro — SIUL2 GPIO Pad Data Input Register
  fields as GPDI3
0x1523 GPDI32 8-bit ro — SIUL2 GPIO Pad Data Input Register
  fields as GPDI3
0x1526 GPDI37 8-bit ro — SIUL2 GPIO Pad Data Input Register
  fields as GPDI3
0x1527 GPDI36 8-bit ro — SIUL2 GPIO Pad Data Input Register
  fields as GPDI3
0x1528 GPDI43 8-bit ro — SIUL2 GPIO Pad Data Input Register
  fields as GPDI3
0x1529 GPDI42 8-bit ro — SIUL2 GPIO Pad Data Input Register
  fields as GPDI3
0x152A GPDI41 8-bit ro — SIUL2 GPIO Pad Data Input Register
  fields as GPDI3
0x152B GPDI40 8-bit ro — SIUL2 GPIO Pad Data Input Register
  fields as GPDI3
0x152C GPDI47 8-bit ro — SIUL2 GPIO Pad Data Input Register
  fields as GPDI3
0x152D GPDI46 8-bit ro — SIUL2 GPIO Pad Data Input Register
  fields as GPDI3
0x152E GPDI45 8-bit ro — SIUL2 GPIO Pad Data Input Register
  fields as GPDI3
0x152F GPDI44 8-bit ro — SIUL2 GPIO Pad Data Input Register
  fields as GPDI3
0x1530 GPDI51 8-bit ro — SIUL2 GPIO Pad Data Input Register
  fields as GPDI3
0x1531 GPDI50 8-bit ro — SIUL2 GPIO Pad Data Input Register
  fields as GPDI3
0x1532 GPDI49 8-bit ro — SIUL2 GPIO Pad Data Input Register
  fields as GPDI3
0x1533 GPDI48 8-bit ro — SIUL2 GPIO Pad Data Input Register
  fields as GPDI3
0x1534 GPDI55 8-bit ro — SIUL2 GPIO Pad Data Input Register
  fields as GPDI3
0x1535 GPDI54 8-bit ro — SIUL2 GPIO Pad Data Input Register
  fields as GPDI3
0x1536 GPDI53 8-bit ro — SIUL2 GPIO Pad Data Input Register
  fields as GPDI3
0x1537 GPDI52 8-bit ro — SIUL2 GPIO Pad Data Input Register
  fields as GPDI3
0x1538 GPDI59 8-bit ro — SIUL2 GPIO Pad Data Input Register
  fields as GPDI3
0x1539 GPDI58 8-bit ro — SIUL2 GPIO Pad Data Input Register
  fields as GPDI3
0x153A GPDI57 8-bit ro — SIUL2 GPIO Pad Data Input Register
  fields as GPDI3
0x153B GPDI56 8-bit ro — SIUL2 GPIO Pad Data Input Register
  fields as GPDI3
0x153C GPDI63 8-bit ro — SIUL2 GPIO Pad Data Input Register
  fields as GPDI3
0x153D GPDI62 8-bit ro — SIUL2 GPIO Pad Data Input Register
  fields as GPDI3
0x153E GPDI61 8-bit ro — SIUL2 GPIO Pad Data Input Register
  fields as GPDI3
0x153F GPDI60 8-bit ro — SIUL2 GPIO Pad Data Input Register
  fields as GPDI3
0x1540 GPDI67 8-bit ro — SIUL2 GPIO Pad Data Input Register
  fields as GPDI3
0x1541 GPDI66 8-bit ro — SIUL2 GPIO Pad Data Input Register
  fields as GPDI3
0x1542 GPDI65 8-bit ro — SIUL2 GPIO Pad Data Input Register
  fields as GPDI3
0x1543 GPDI64 8-bit ro — SIUL2 GPIO Pad Data Input Register
  fields as GPDI3
0x1544 GPDI71 8-bit ro — SIUL2 GPIO Pad Data Input Register
  fields as GPDI3
0x1545 GPDI70 8-bit ro — SIUL2 GPIO Pad Data Input Register
  fields as GPDI3
0x1546 GPDI69 8-bit ro — SIUL2 GPIO Pad Data Input Register
  fields as GPDI3
0x1547 GPDI68 8-bit ro — SIUL2 GPIO Pad Data Input Register
  fields as GPDI3
0x1548 GPDI75 8-bit ro — SIUL2 GPIO Pad Data Input Register
  fields as GPDI3
0x1549 GPDI74 8-bit ro — SIUL2 GPIO Pad Data Input Register
  fields as GPDI3
0x154A GPDI73 8-bit ro — SIUL2 GPIO Pad Data Input Register
  fields as GPDI3
0x154B GPDI72 8-bit ro — SIUL2 GPIO Pad Data Input Register
  fields as GPDI3
0x154C GPDI79 8-bit ro — SIUL2 GPIO Pad Data Input Register
  fields as GPDI3
0x154D GPDI78 8-bit ro — SIUL2 GPIO Pad Data Input Register
  fields as GPDI3
0x154E GPDI77 8-bit ro — SIUL2 GPIO Pad Data Input Register
  fields as GPDI3
0x154F GPDI76 8-bit ro — SIUL2 GPIO Pad Data Input Register
  fields as GPDI3
0x1550 GPDI83 8-bit ro — SIUL2 GPIO Pad Data Input Register
  fields as GPDI3
0x1551 GPDI82 8-bit ro — SIUL2 GPIO Pad Data Input Register
  fields as GPDI3
0x1552 GPDI81 8-bit ro — SIUL2 GPIO Pad Data Input Register
  fields as GPDI3
0x1553 GPDI80 8-bit ro — SIUL2 GPIO Pad Data Input Register
  fields as GPDI3
0x1554 GPDI87 8-bit ro — SIUL2 GPIO Pad Data Input Register
  fields as GPDI3
0x1555 GPDI86 8-bit ro — SIUL2 GPIO Pad Data Input Register
  fields as GPDI3
0x1556 GPDI85 8-bit ro — SIUL2 GPIO Pad Data Input Register
  fields as GPDI3
0x1557 GPDI84 8-bit ro — SIUL2 GPIO Pad Data Input Register
  fields as GPDI3
0x1558 GPDI91 8-bit ro — SIUL2 GPIO Pad Data Input Register
  fields as GPDI3
0x1559 GPDI90 8-bit ro — SIUL2 GPIO Pad Data Input Register
  fields as GPDI3
0x155A GPDI89 8-bit ro — SIUL2 GPIO Pad Data Input Register
  fields as GPDI3
0x155B GPDI88 8-bit ro — SIUL2 GPIO Pad Data Input Register
  fields as GPDI3
0x155C GPDI95 8-bit ro — SIUL2 GPIO Pad Data Input Register
  fields as GPDI3
0x155D GPDI94 8-bit ro — SIUL2 GPIO Pad Data Input Register
  fields as GPDI3
0x155E GPDI93 8-bit ro — SIUL2 GPIO Pad Data Input Register
  fields as GPDI3
0x155F GPDI92 8-bit ro — SIUL2 GPIO Pad Data Input Register
  fields as GPDI3
0x1560 GPDI99 8-bit ro — SIUL2 GPIO Pad Data Input Register
  fields as GPDI3
0x1561 GPDI98 8-bit ro — SIUL2 GPIO Pad Data Input Register
  fields as GPDI3
0x1562 GPDI97 8-bit ro — SIUL2 GPIO Pad Data Input Register
  fields as GPDI3
0x1563 GPDI96 8-bit ro — SIUL2 GPIO Pad Data Input Register
  fields as GPDI3
0x1564 GPDI103 8-bit ro — SIUL2 GPIO Pad Data Input Register
  fields as GPDI3
0x1565 GPDI102 8-bit ro — SIUL2 GPIO Pad Data Input Register
  fields as GPDI3
0x1566 GPDI101 8-bit ro — SIUL2 GPIO Pad Data Input Register
  fields as GPDI3
0x1567 GPDI100 8-bit ro — SIUL2 GPIO Pad Data Input Register
  fields as GPDI3
0x1568 GPDI107 8-bit ro — SIUL2 GPIO Pad Data Input Register
  fields as GPDI3
0x1569 GPDI106 8-bit ro — SIUL2 GPIO Pad Data Input Register
  fields as GPDI3
0x156A GPDI105 8-bit ro — SIUL2 GPIO Pad Data Input Register
  fields as GPDI3
0x156B GPDI104 8-bit ro — SIUL2 GPIO Pad Data Input Register
  fields as GPDI3
0x156C GPDI111 8-bit ro — SIUL2 GPIO Pad Data Input Register
  fields as GPDI3
0x156D GPDI110 8-bit ro — SIUL2 GPIO Pad Data Input Register
  fields as GPDI3
0x156E GPDI109 8-bit ro — SIUL2 GPIO Pad Data Input Register
  fields as GPDI3
0x156F GPDI108 8-bit ro — SIUL2 GPIO Pad Data Input Register
  fields as GPDI3
0x1570 GPDI115 8-bit ro — SIUL2 GPIO Pad Data Input Register
  fields as GPDI3
0x1571 GPDI114 8-bit ro — SIUL2 GPIO Pad Data Input Register
  fields as GPDI3
0x1572 GPDI113 8-bit ro — SIUL2 GPIO Pad Data Input Register
  fields as GPDI3
0x1573 GPDI112 8-bit ro — SIUL2 GPIO Pad Data Input Register
  fields as GPDI3
0x1574 GPDI119 8-bit ro — SIUL2 GPIO Pad Data Input Register
  fields as GPDI3
0x1575 GPDI118 8-bit ro — SIUL2 GPIO Pad Data Input Register
  fields as GPDI3
0x1576 GPDI117 8-bit ro — SIUL2 GPIO Pad Data Input Register
  fields as GPDI3
0x1577 GPDI116 8-bit ro — SIUL2 GPIO Pad Data Input Register
  fields as GPDI3
0x1578 GPDI123 8-bit ro — SIUL2 GPIO Pad Data Input Register
  fields as GPDI3
0x1579 GPDI122 8-bit ro — SIUL2 GPIO Pad Data Input Register
  fields as GPDI3
0x157A GPDI121 8-bit ro — SIUL2 GPIO Pad Data Input Register
  fields as GPDI3
0x157B GPDI120 8-bit ro — SIUL2 GPIO Pad Data Input Register
  fields as GPDI3
0x157C GPDI127 8-bit ro — SIUL2 GPIO Pad Data Input Register
  fields as GPDI3
0x157D GPDI126 8-bit ro — SIUL2 GPIO Pad Data Input Register
  fields as GPDI3
0x157E GPDI125 8-bit ro — SIUL2 GPIO Pad Data Input Register
  fields as GPDI3
0x157F GPDI124 8-bit ro — SIUL2 GPIO Pad Data Input Register
  fields as GPDI3
0x1580 GPDI131 8-bit ro — SIUL2 GPIO Pad Data Input Register
  fields as GPDI3
0x1581 GPDI130 8-bit ro — SIUL2 GPIO Pad Data Input Register
  fields as GPDI3
0x1582 GPDI129 8-bit ro — SIUL2 GPIO Pad Data Input Register
  fields as GPDI3
0x1583 GPDI128 8-bit ro — SIUL2 GPIO Pad Data Input Register
  fields as GPDI3
0x1584 GPDI135 8-bit ro — SIUL2 GPIO Pad Data Input Register
  fields as GPDI3
0x1585 GPDI134 8-bit ro — SIUL2 GPIO Pad Data Input Register
  fields as GPDI3
0x1586 GPDI133 8-bit ro — SIUL2 GPIO Pad Data Input Register
  fields as GPDI3
0x1587 GPDI132 8-bit ro — SIUL2 GPIO Pad Data Input Register
  fields as GPDI3
0x1588 GPDI139 8-bit ro — SIUL2 GPIO Pad Data Input Register
  fields as GPDI3
0x1589 GPDI138 8-bit ro — SIUL2 GPIO Pad Data Input Register
  fields as GPDI3
0x158A GPDI137 8-bit ro — SIUL2 GPIO Pad Data Input Register
  fields as GPDI3
0x158B GPDI136 8-bit ro — SIUL2 GPIO Pad Data Input Register
  fields as GPDI3
0x158C GPDI143 8-bit ro — SIUL2 GPIO Pad Data Input Register
  fields as GPDI3
0x158D GPDI142 8-bit ro — SIUL2 GPIO Pad Data Input Register
  fields as GPDI3
0x158E GPDI141 8-bit ro — SIUL2 GPIO Pad Data Input Register
  fields as GPDI3
0x158F GPDI140 8-bit ro — SIUL2 GPIO Pad Data Input Register
  fields as GPDI3
0x1590 GPDI147 8-bit ro — SIUL2 GPIO Pad Data Input Register
  fields as GPDI3
0x1591 GPDI146 8-bit ro — SIUL2 GPIO Pad Data Input Register
  fields as GPDI3
0x1592 GPDI145 8-bit ro — SIUL2 GPIO Pad Data Input Register
  fields as GPDI3
0x1593 GPDI144 8-bit ro — SIUL2 GPIO Pad Data Input Register
  fields as GPDI3
0x1594 GPDI151 8-bit ro — SIUL2 GPIO Pad Data Input Register
  fields as GPDI3
0x1595 GPDI150 8-bit ro — SIUL2 GPIO Pad Data Input Register
  fields as GPDI3
0x1596 GPDI149 8-bit ro — SIUL2 GPIO Pad Data Input Register
  fields as GPDI3
0x1597 GPDI148 8-bit ro — SIUL2 GPIO Pad Data Input Register
  fields as GPDI3
0x1598 GPDI155 8-bit ro — SIUL2 GPIO Pad Data Input Register
  fields as GPDI3
0x1599 GPDI154 8-bit ro — SIUL2 GPIO Pad Data Input Register
  fields as GPDI3
0x159A GPDI153 8-bit ro — SIUL2 GPIO Pad Data Input Register
  fields as GPDI3
0x159B GPDI152 8-bit ro — SIUL2 GPIO Pad Data Input Register
  fields as GPDI3
0x159C GPDI159 8-bit ro — SIUL2 GPIO Pad Data Input Register
  fields as GPDI3
0x159D GPDI158 8-bit ro — SIUL2 GPIO Pad Data Input Register
  fields as GPDI3
0x159E GPDI157 8-bit ro — SIUL2 GPIO Pad Data Input Register
  fields as GPDI3
0x159F GPDI156 8-bit ro — SIUL2 GPIO Pad Data Input Register
  fields as GPDI3
0x15A0 GPDI163 8-bit ro — SIUL2 GPIO Pad Data Input Register
  fields as GPDI3
0x15A1 GPDI162 8-bit ro — SIUL2 GPIO Pad Data Input Register
  fields as GPDI3
0x15A2 GPDI161 8-bit ro — SIUL2 GPIO Pad Data Input Register
  fields as GPDI3
0x15A3 GPDI160 8-bit ro — SIUL2 GPIO Pad Data Input Register
  fields as GPDI3
0x15A4 GPDI167 8-bit ro — SIUL2 GPIO Pad Data Input Register
  fields as GPDI3
0x15A5 GPDI166 8-bit ro — SIUL2 GPIO Pad Data Input Register
  fields as GPDI3
0x15A6 GPDI165 8-bit ro — SIUL2 GPIO Pad Data Input Register
  fields as GPDI3
0x15A7 GPDI164 8-bit ro — SIUL2 GPIO Pad Data Input Register
  fields as GPDI3
0x15A8 GPDI171 8-bit ro — SIUL2 GPIO Pad Data Input Register
  fields as GPDI3
0x15A9 GPDI170 8-bit ro — SIUL2 GPIO Pad Data Input Register
  fields as GPDI3
0x15AA GPDI169 8-bit ro — SIUL2 GPIO Pad Data Input Register
  fields as GPDI3
0x15AB GPDI168 8-bit ro — SIUL2 GPIO Pad Data Input Register
  fields as GPDI3
0x15AC GPDI175 8-bit ro — SIUL2 GPIO Pad Data Input Register
  fields as GPDI3
0x15AD GPDI174 8-bit ro — SIUL2 GPIO Pad Data Input Register
  fields as GPDI3
0x15AE GPDI173 8-bit ro — SIUL2 GPIO Pad Data Input Register
  fields as GPDI3
0x15AF GPDI172 8-bit ro — SIUL2 GPIO Pad Data Input Register
  fields as GPDI3
0x15B0 GPDI179 8-bit ro — SIUL2 GPIO Pad Data Input Register
  fields as GPDI3
0x15B1 GPDI178 8-bit ro — SIUL2 GPIO Pad Data Input Register
  fields as GPDI3
0x15B2 GPDI177 8-bit ro — SIUL2 GPIO Pad Data Input Register
  fields as GPDI3
0x15B3 GPDI176 8-bit ro — SIUL2 GPIO Pad Data Input Register
  fields as GPDI3
0x15B4 GPDI183 8-bit ro — SIUL2 GPIO Pad Data Input Register
  fields as GPDI3
0x15B5 GPDI182 8-bit ro — SIUL2 GPIO Pad Data Input Register
  fields as GPDI3
0x15B6 GPDI181 8-bit ro — SIUL2 GPIO Pad Data Input Register
  fields as GPDI3
0x15B7 GPDI180 8-bit ro — SIUL2 GPIO Pad Data Input Register
  fields as GPDI3
0x15B8 GPDI187 8-bit ro — SIUL2 GPIO Pad Data Input Register
  fields as GPDI3
0x15B9 GPDI186 8-bit ro — SIUL2 GPIO Pad Data Input Register
  fields as GPDI3
0x15BA GPDI185 8-bit ro — SIUL2 GPIO Pad Data Input Register
  fields as GPDI3
0x15BB GPDI184 8-bit ro — SIUL2 GPIO Pad Data Input Register
  fields as GPDI3
0x15BC GPDI191 8-bit ro — SIUL2 GPIO Pad Data Input Register
  fields as GPDI3
0x15BD GPDI190 8-bit ro — SIUL2 GPIO Pad Data Input Register
  fields as GPDI3
0x15BE GPDI189 8-bit ro — SIUL2 GPIO Pad Data Input Register
  fields as GPDI3
0x15BF GPDI188 8-bit ro — SIUL2 GPIO Pad Data Input Register
  fields as GPDI3
0x15C0 GPDI195 8-bit ro — SIUL2 GPIO Pad Data Input Register
  fields as GPDI3
0x15C1 GPDI194 8-bit ro — SIUL2 GPIO Pad Data Input Register
  fields as GPDI3
0x15C2 GPDI193 8-bit ro — SIUL2 GPIO Pad Data Input Register
  fields as GPDI3
0x15C3 GPDI192 8-bit ro — SIUL2 GPIO Pad Data Input Register
  fields as GPDI3
0x15C4 GPDI199 8-bit ro — SIUL2 GPIO Pad Data Input Register
  fields as GPDI3
0x15C5 GPDI198 8-bit ro — SIUL2 GPIO Pad Data Input Register
  fields as GPDI3
0x15C6 GPDI197 8-bit ro — SIUL2 GPIO Pad Data Input Register
  fields as GPDI3
0x15C7 GPDI196 8-bit ro — SIUL2 GPIO Pad Data Input Register
  fields as GPDI3
0x15C8 GPDI203 8-bit ro — SIUL2 GPIO Pad Data Input Register
  fields as GPDI3
0x15C9 GPDI202 8-bit ro — SIUL2 GPIO Pad Data Input Register
  fields as GPDI3
0x15CA GPDI201 8-bit ro — SIUL2 GPIO Pad Data Input Register
  fields as GPDI3
0x15CB GPDI200 8-bit ro — SIUL2 GPIO Pad Data Input Register
  fields as GPDI3
0x15CC GPDI207 8-bit ro — SIUL2 GPIO Pad Data Input Register
  fields as GPDI3
0x15CD GPDI206 8-bit ro — SIUL2 GPIO Pad Data Input Register
  fields as GPDI3
0x15CE GPDI205 8-bit ro — SIUL2 GPIO Pad Data Input Register
  fields as GPDI3
0x15CF GPDI204 8-bit ro — SIUL2 GPIO Pad Data Input Register
  fields as GPDI3
0x15D0 GPDI211 8-bit ro — SIUL2 GPIO Pad Data Input Register
  fields as GPDI3
0x15D1 GPDI210 8-bit ro — SIUL2 GPIO Pad Data Input Register
  fields as GPDI3
0x15D2 GPDI209 8-bit ro — SIUL2 GPIO Pad Data Input Register
  fields as GPDI3
0x15D3 GPDI208 8-bit ro — SIUL2 GPIO Pad Data Input Register
  fields as GPDI3
0x15D4 GPDI215 8-bit ro — SIUL2 GPIO Pad Data Input Register
  fields as GPDI3
0x15D5 GPDI214 8-bit ro — SIUL2 GPIO Pad Data Input Register
  fields as GPDI3
0x15D6 GPDI213 8-bit ro — SIUL2 GPIO Pad Data Input Register
  fields as GPDI3
0x15D7 GPDI212 8-bit ro — SIUL2 GPIO Pad Data Input Register
  fields as GPDI3
0x15D8 GPDI219 8-bit ro — SIUL2 GPIO Pad Data Input Register
  fields as GPDI3
0x15D9 GPDI218 8-bit ro — SIUL2 GPIO Pad Data Input Register
  fields as GPDI3
0x15DA GPDI217 8-bit ro — SIUL2 GPIO Pad Data Input Register
  fields as GPDI3
0x15DB GPDI216 8-bit ro — SIUL2 GPIO Pad Data Input Register
  fields as GPDI3
0x1700 PGPDO1 16-bit — SIUL2 Parallel GPIO Pad Data Out Register
  [n] PPDO{n} (n=0..15) — Parallel Pad Data Out {n}
0x1702 PGPDO0 16-bit — SIUL2 Parallel GPIO Pad Data Out Register
  [n] PPDO{n} (n=0..15) — Parallel Pad Data Out {n}
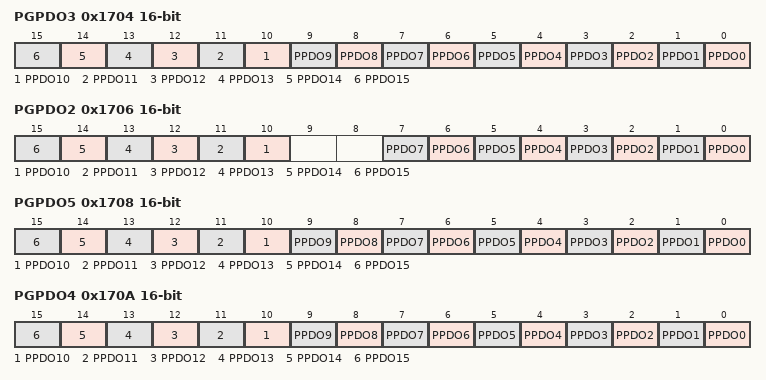
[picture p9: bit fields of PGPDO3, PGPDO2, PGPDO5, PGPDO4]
0x1704 PGPDO3 16-bit — SIUL2 Parallel GPIO Pad Data Out Register
  [n] PPDO{n} (n=0..15) — Parallel Pad Data Out {n}
0x1706 PGPDO2 16-bit — SIUL2 Parallel GPIO Pad Data Out Register
  [n] PPDO{n} (n=10..15) — Parallel Pad Data Out {n}
  [n] PPDO{n} (n=0..7) — Parallel Pad Data Out {n}
0x1708 PGPDO5 16-bit — SIUL2 Parallel GPIO Pad Data Out Register
  [n] PPDO{n} (n=0..15) — Parallel Pad Data Out {n}
0x170A PGPDO4 16-bit — SIUL2 Parallel GPIO Pad Data Out Register
  [n] PPDO{n} (n=0..15) — Parallel Pad Data Out {n}
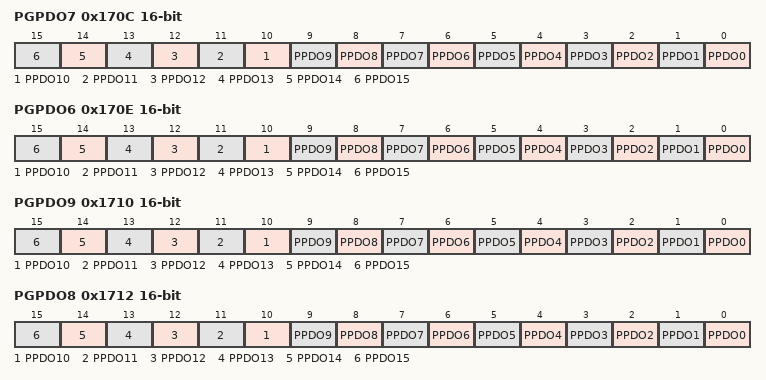
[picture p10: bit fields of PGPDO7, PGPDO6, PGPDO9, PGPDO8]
0x170C PGPDO7 16-bit — SIUL2 Parallel GPIO Pad Data Out Register
  [n] PPDO{n} (n=0..15) — Parallel Pad Data Out {n}
0x170E PGPDO6 16-bit — SIUL2 Parallel GPIO Pad Data Out Register
  [n] PPDO{n} (n=0..15) — Parallel Pad Data Out {n}
0x1710 PGPDO9 16-bit — SIUL2 Parallel GPIO Pad Data Out Register
  [n] PPDO{n} (n=0..15) — Parallel Pad Data Out {n}
0x1712 PGPDO8 16-bit — SIUL2 Parallel GPIO Pad Data Out Register
  [n] PPDO{n} (n=0..15) — Parallel Pad Data Out {n}
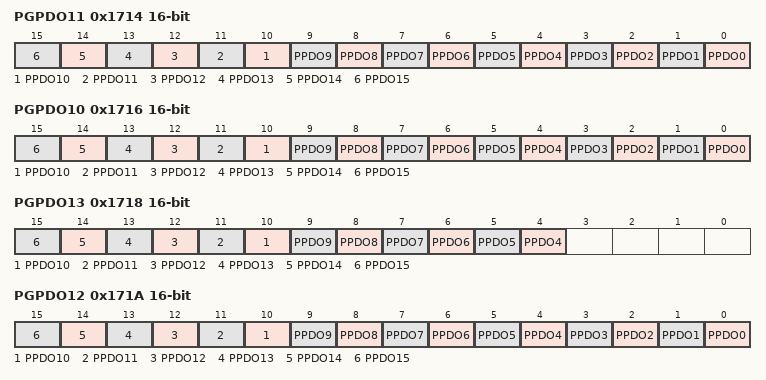
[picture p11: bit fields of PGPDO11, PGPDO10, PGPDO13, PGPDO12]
0x1714 PGPDO11 16-bit — SIUL2 Parallel GPIO Pad Data Out Register
  [n] PPDO{n} (n=0..15) — Parallel Pad Data Out {n}
0x1716 PGPDO10 16-bit — SIUL2 Parallel GPIO Pad Data Out Register
  [n] PPDO{n} (n=0..15) — Parallel Pad Data Out {n}
0x1718 PGPDO13 16-bit — SIUL2 Parallel GPIO Pad Data Out Register
  [n] PPDO{n} (n=4..15) — Parallel Pad Data Out {n}
0x171A PGPDO12 16-bit — SIUL2 Parallel GPIO Pad Data Out Register
  [n] PPDO{n} (n=0..15) — Parallel Pad Data Out {n}
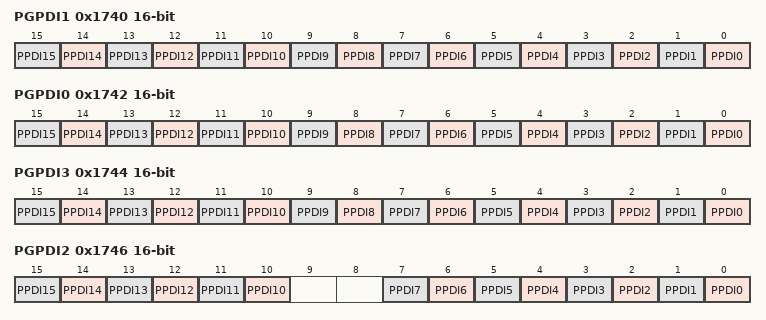
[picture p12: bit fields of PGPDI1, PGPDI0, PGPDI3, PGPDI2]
0x1740 PGPDI1 16-bit ro — SIUL2 Parallel GPIO Pad Data In Register
  [n] PPDI{n} (n=0..15) — Parallel Pad Data In {n}
0x1742 PGPDI0 16-bit ro — SIUL2 Parallel GPIO Pad Data In Register
  [n] PPDI{n} (n=0..15) — Parallel Pad Data In {n}
0x1744 PGPDI3 16-bit ro — SIUL2 Parallel GPIO Pad Data In Register
  [n] PPDI{n} (n=0..15) — Parallel Pad Data In {n}
0x1746 PGPDI2 16-bit ro — SIUL2 Parallel GPIO Pad Data In Register
  [n] PPDI{n} (n=10..15) — Parallel Pad Data In {n}
  [n] PPDI{n} (n=0..7) — Parallel Pad Data In {n}
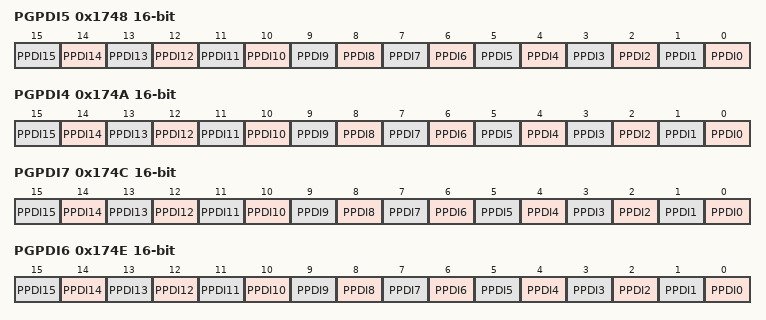
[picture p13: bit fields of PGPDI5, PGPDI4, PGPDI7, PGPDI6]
0x1748 PGPDI5 16-bit ro — SIUL2 Parallel GPIO Pad Data In Register
  [n] PPDI{n} (n=0..15) — Parallel Pad Data In {n}
0x174A PGPDI4 16-bit ro — SIUL2 Parallel GPIO Pad Data In Register
  [n] PPDI{n} (n=0..15) — Parallel Pad Data In {n}
0x174C PGPDI7 16-bit ro — SIUL2 Parallel GPIO Pad Data In Register
  [n] PPDI{n} (n=0..15) — Parallel Pad Data In {n}
0x174E PGPDI6 16-bit ro — SIUL2 Parallel GPIO Pad Data In Register
  [n] PPDI{n} (n=0..15) — Parallel Pad Data In {n}
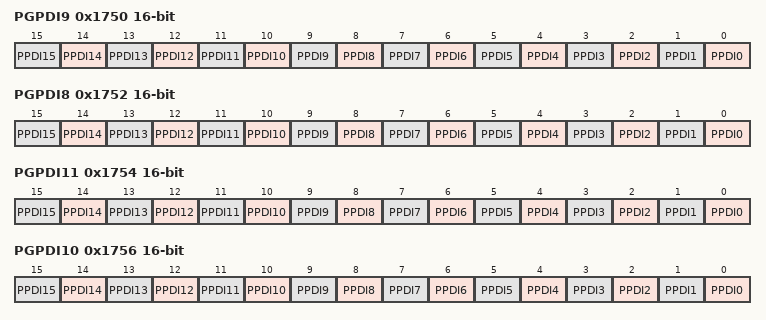
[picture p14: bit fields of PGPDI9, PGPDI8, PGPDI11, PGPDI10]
0x1750 PGPDI9 16-bit ro — SIUL2 Parallel GPIO Pad Data In Register
  [n] PPDI{n} (n=0..15) — Parallel Pad Data In {n}
0x1752 PGPDI8 16-bit ro — SIUL2 Parallel GPIO Pad Data In Register
  [n] PPDI{n} (n=0..15) — Parallel Pad Data In {n}
0x1754 PGPDI11 16-bit ro — SIUL2 Parallel GPIO Pad Data In Register
  [n] PPDI{n} (n=0..15) — Parallel Pad Data In {n}
0x1756 PGPDI10 16-bit ro — SIUL2 Parallel GPIO Pad Data In Register
  [n] PPDI{n} (n=0..15) — Parallel Pad Data In {n}
0x1758 PGPDI13 16-bit ro — SIUL2 Parallel GPIO Pad Data In Register
  [n] PPDI{n} (n=4..15) — Parallel Pad Data In {n}
0x175A PGPDI12 16-bit ro — SIUL2 Parallel GPIO Pad Data In Register
  [n] PPDI{n} (n=0..15) — Parallel Pad Data In {n}
0x1780 MPGPDO0 — SIUL2 Masked Parallel GPIO Pad Data Out Register
  [n+16] MASK{n} (n=0..15) — Mask Field {n}
    0=MASK_IGNORED (MPPDO{n} is ignored); 1=MASK_WRITTEN (MPPDO{n} is written)
  [n] MPPDO{n} (n=0..15) — Masked Parallel Pad Data Out {n}
0x1784 MPGPDO1 — SIUL2 Masked Parallel GPIO Pad Data Out Register
  fields as MPGPDO0
0x1788 MPGPDO2 — SIUL2 Masked Parallel GPIO Pad Data Out Register
  [n+16] MASK{n} (n=10..15) — Mask Field {n}
    values as MPGPDO0.MASK0
  [n+16] MASK{n} (n=0..7) — Mask Field {n}
    values as MPGPDO0.MASK0
  [n] MPPDO{n} (n=10..15) — Masked Parallel Pad Data Out {n}
  [n] MPPDO{n} (n=0..7) — Masked Parallel Pad Data Out {n}
{0x1780+4i} MPGPDO{i} (i=3..12) — SIUL2 Masked Parallel GPIO Pad Data Out Register
  fields as MPGPDO0
0x17B4 MPGPDO13 — SIUL2 Masked Parallel GPIO Pad Data Out Register
  [n+16] MASK{n} (n=4..15) — Mask Field {n}
    values as MPGPDO0.MASK0
  [n] MPPDO{n} (n=4..15) — Masked Parallel Pad Data Out {n}
